# MIMXRT1042 register map
Vendor: nxp.com; File version: 1.0
CPU: CM7 r0p1, little endian, MPU, FPU, VTOR, 4 interrupt priority bits
Registers are 32-bit, read-write, reset 0x0 unless marked. A register's access mark holds for its fields unless they carry their own. Offsets are from the block's base; [hi:lo] are bit positions; 'fields as' and 'values as' point back to an identical list.

## XTALOSC24M
Base 0x400D8000; register names take the prefix XTALOSC24M_; alternate view of CCM_ANALOG
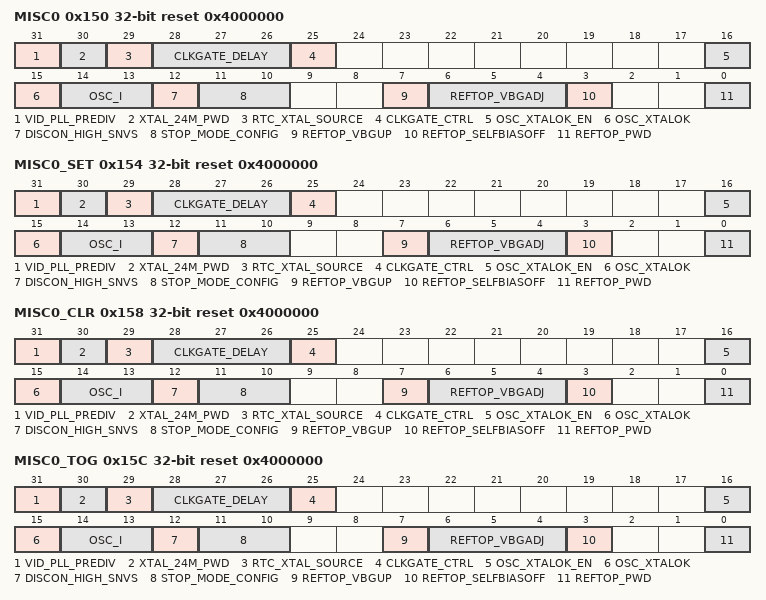
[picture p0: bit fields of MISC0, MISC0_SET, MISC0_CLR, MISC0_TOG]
0x150 MISC0 reset 0x4000000 — Miscellaneous Register 0
  [31] VID_PLL_PREDIV — Predivider for the source clock of the PLL's. Not related to oscillator.
    0=Divide by 1; 1=Divide by 2
  [30] XTAL_24M_PWD — This field powers down the 24M crystal oscillator if set true.
  [29] RTC_XTAL_SOURCE ro — This field indicates which chip source is being used for the rtc clock.
    0=Internal ring oscillator; 1=RTC_XTAL
  [28:26] CLKGATE_DELAY — This field specifies the delay between powering up the XTAL 24MHz clock and releasing the clock to the digital logic inside the analog block
    0=0.5ms; 1=1.0ms; 2=2.0ms; 3=3.0ms; 4=4.0ms; 5=5.0ms; 6=6.0ms; 7=7.0ms
  [25] CLKGATE_CTRL — This bit allows disabling the clock gate (always ungated) for the xtal 24MHz clock that clocks the digital logic in the analog block
    0=ALLOW_AUTO_GATE (Allow the logic to automatically gate the clock when the XTAL is powered down.); 1=NO_AUTO_GATE (Prevent the logic from ever gating off the clock.)
  [16] OSC_XTALOK_EN — This bit enables the detector that signals when the 24MHz crystal oscillator is stable.
  [15] OSC_XTALOK ro — Status bit that signals that the output of the 24-MHz crystal oscillator is stable
  [14:13] OSC_I — This field determines the bias current in the 24MHz oscillator
    0=NOMINAL; 1=MINUS_12_5_PERCENT (Decrease current by 12.5%); 2=MINUS_25_PERCENT (Decrease current by 25.0%); 3=MINUS_37_5_PERCENT (Decrease current by 37.5%)
  [12] DISCON_HIGH_SNVS — This bit controls a switch from VDD_HIGH_IN to VDD_SNVS_IN.
    0=Turn on the switch; 1=Turn off the switch
  [11:10] STOP_MODE_CONFIG — Configure the analog behavior in stop mode. Not related to oscillator.
    0=All analog except rtc powered down on stop mode assertion. XtalOsc=on, RCOsc=off;; 1=Certain analog functions such as certain regulators left up. XtalOsc=on, RCOsc=off;; 2=XtalOsc=off, RCOsc=on, Old BG=on, New BG=off; 3=XtalOsc=off, RCOsc=on, Old BG=off, New BG=on
  [7] REFTOP_VBGUP — Status bit that signals the analog bandgap voltage is up and stable
  [6:4] REFTOP_VBGADJ — Not related to oscillator.
    0=Nominal VBG; 1=VBG+0.78%; 2=VBG+1.56%; 3=VBG+2.34%; 4=VBG-0.78%; 5=VBG-1.56%; 6=VBG-2.34%; 7=VBG-3.12%
  [3] REFTOP_SELFBIASOFF — Control bit to disable the self-bias circuit in the analog bandgap
    0=Uses coarse bias currents for startup; 1=Uses bandgap-based bias currents for best performance
  [0] REFTOP_PWD — Control bit to power-down the analog bandgap reference circuitry
0x154 MISC0_SET reset 0x4000000 — Miscellaneous Register 0
  fields as MISC0
0x158 MISC0_CLR reset 0x4000000 — Miscellaneous Register 0
  fields as MISC0
0x15C MISC0_TOG reset 0x4000000 — Miscellaneous Register 0
  fields as MISC0
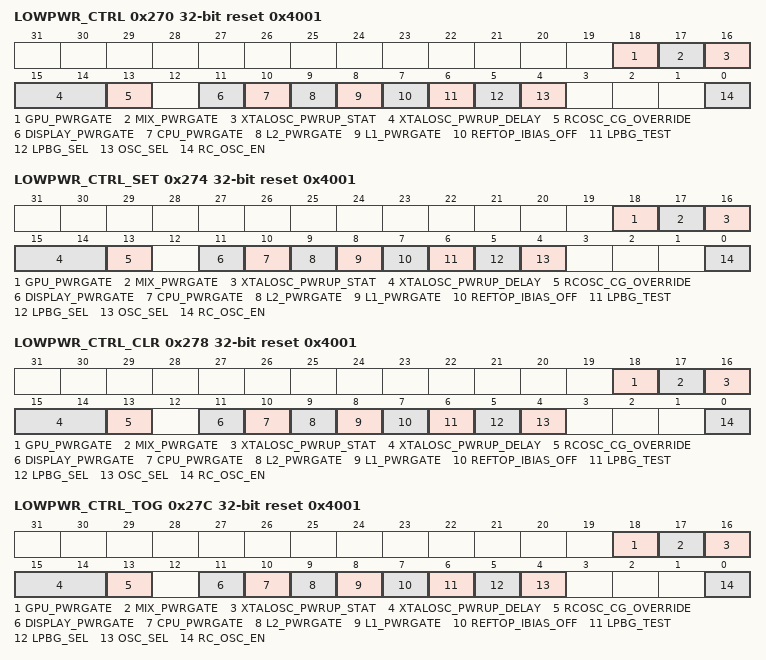
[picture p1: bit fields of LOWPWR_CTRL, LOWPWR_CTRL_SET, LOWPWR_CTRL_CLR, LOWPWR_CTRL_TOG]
0x270 LOWPWR_CTRL reset 0x4001 — XTAL OSC (LP) Control Register
  [18] GPU_PWRGATE — GPU power gate control. Used as software mask. Set to zero to force ungated.
  [17] MIX_PWRGATE — Display power gate control. Used as software mask. Set to zero to force ungated.
  [16] XTALOSC_PWRUP_STAT ro — Status of the 24MHz xtal oscillator.
    0=Not stable; 1=Stable and ready to use
  [15:14] XTALOSC_PWRUP_DELAY — Specifies the time delay between when the 24MHz xtal is powered up until it is stable and ready to use
    0=0.25ms; 1=0.5ms; 2=1ms; 3=2ms
  [13] RCOSC_CG_OVERRIDE — For debug purposes only
  [11] DISPLAY_PWRGATE — Display logic power gate control. Used as software override. Not related to oscillator.
  [10] CPU_PWRGATE — CPU power gate control. Used as software override. Test purpose only Not related to oscillator.
  [9] L2_PWRGATE — L2 power gate control. Used as software override. Not related to oscillator.
  [8] L1_PWRGATE — L1 power gate control. Used as software override. Not related to oscillator.
  [7] REFTOP_IBIAS_OFF — Low power reftop ibias disable. Not related to oscillator.
  [6] LPBG_TEST — Low power bandgap test bit. Not related to oscillator.
  [5] LPBG_SEL — Bandgap select. Not related to oscillator.
    0=Normal power bandgap; 1=Low power bandgap
  [4] OSC_SEL — Select the source for the 24MHz clock.
    0=XTAL OSC; 1=RC OSC
  [0] RC_OSC_EN — RC Osc. enable control.
    0=Use XTAL OSC to source the 24MHz clock; 1=Use RC OSC
0x274 LOWPWR_CTRL_SET reset 0x4001 — XTAL OSC (LP) Control Register
  fields as LOWPWR_CTRL
0x278 LOWPWR_CTRL_CLR reset 0x4001 — XTAL OSC (LP) Control Register
  fields as LOWPWR_CTRL
0x27C LOWPWR_CTRL_TOG reset 0x4001 — XTAL OSC (LP) Control Register
  fields as LOWPWR_CTRL
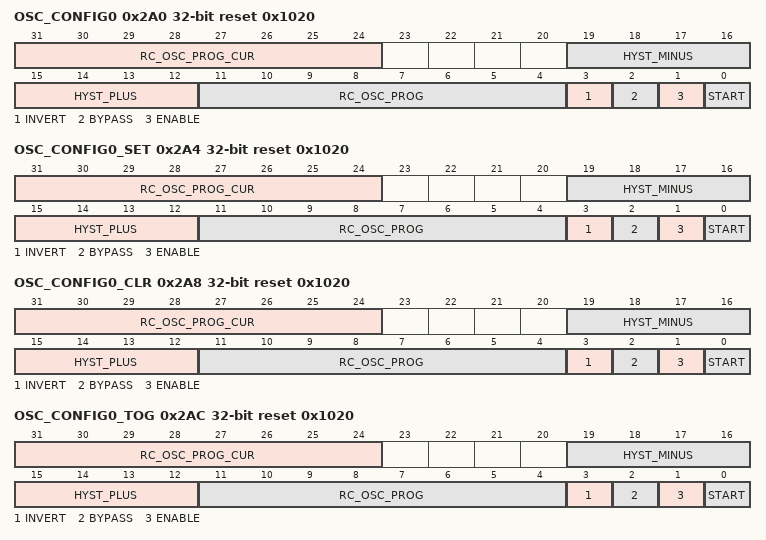
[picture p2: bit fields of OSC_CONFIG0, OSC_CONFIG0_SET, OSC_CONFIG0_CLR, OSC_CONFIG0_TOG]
0x2A0 OSC_CONFIG0 reset 0x1020 — XTAL OSC Configuration 0 Register
  [31:24] RC_OSC_PROG_CUR — The current tuning value in use.
  [19:16] HYST_MINUS — Negative hysteresis value
  [15:12] HYST_PLUS — Positive hysteresis value
  [11:4] RC_OSC_PROG — RC osc. tuning values.
  [3] INVERT — Invert the stepping of the calculated RC tuning value.
  [2] BYPASS — Bypasses any calculated RC tuning value and uses the programmed register value.
  [1] ENABLE — Enables the tuning logic to calculate new RC tuning values
  [0] START — Start/stop bit for the RC tuning calculation logic. If stopped the tuning logic is reset.
0x2A4 OSC_CONFIG0_SET reset 0x1020 — XTAL OSC Configuration 0 Register
  fields as OSC_CONFIG0
0x2A8 OSC_CONFIG0_CLR reset 0x1020 — XTAL OSC Configuration 0 Register
  fields as OSC_CONFIG0
0x2AC OSC_CONFIG0_TOG reset 0x1020 — XTAL OSC Configuration 0 Register
  fields as OSC_CONFIG0
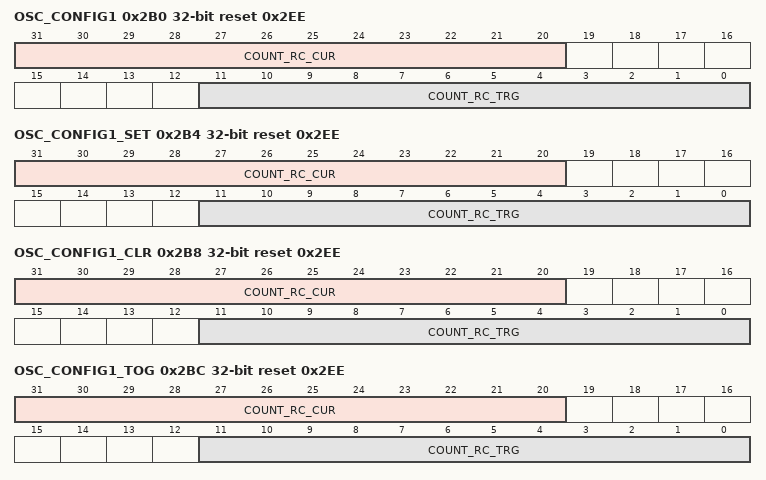
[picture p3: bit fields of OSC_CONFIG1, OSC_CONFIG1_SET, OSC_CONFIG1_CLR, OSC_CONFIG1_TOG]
0x2B0 OSC_CONFIG1 reset 0x2EE — XTAL OSC Configuration 1 Register
  [31:20] COUNT_RC_CUR — The current tuning value in use.
  [11:0] COUNT_RC_TRG — The target count used to tune the RC OSC frequency
0x2B4 OSC_CONFIG1_SET reset 0x2EE — XTAL OSC Configuration 1 Register
  fields as OSC_CONFIG1
0x2B8 OSC_CONFIG1_CLR reset 0x2EE — XTAL OSC Configuration 1 Register
  fields as OSC_CONFIG1
0x2BC OSC_CONFIG1_TOG reset 0x2EE — XTAL OSC Configuration 1 Register
  fields as OSC_CONFIG1
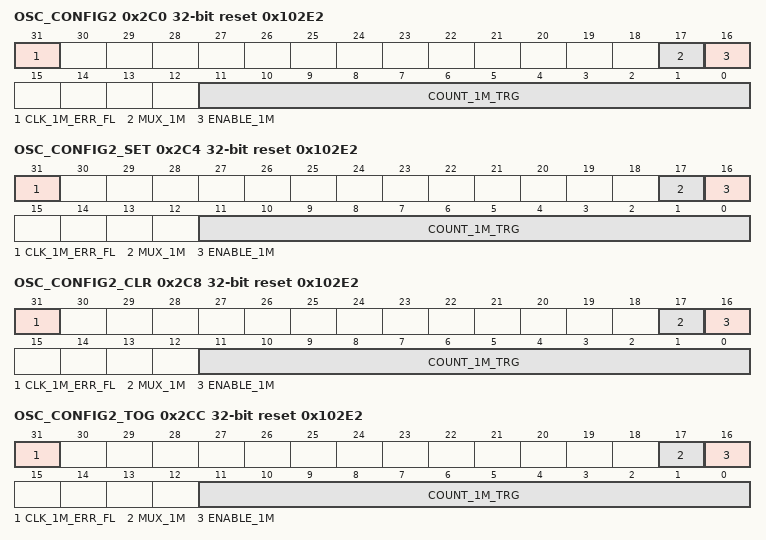
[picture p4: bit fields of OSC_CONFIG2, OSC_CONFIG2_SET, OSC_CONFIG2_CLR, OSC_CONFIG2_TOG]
0x2C0 OSC_CONFIG2 reset 0x102E2 — XTAL OSC Configuration 2 Register
  [31] CLK_1M_ERR_FL — Flag indicates that the count_1m count wasn't reached within 1 32kHz period
  [17] MUX_1M — Mux the corrected or uncorrected 1MHz clock to the output
  [16] ENABLE_1M — Enable the 1MHz clock output. 0 - disabled; 1 - enabled.
  [11:0] COUNT_1M_TRG — The target count used to tune the 1MHz clock frequency
0x2C4 OSC_CONFIG2_SET reset 0x102E2 — XTAL OSC Configuration 2 Register
  fields as OSC_CONFIG2
0x2C8 OSC_CONFIG2_CLR reset 0x102E2 — XTAL OSC Configuration 2 Register
  fields as OSC_CONFIG2
0x2CC OSC_CONFIG2_TOG reset 0x102E2 — XTAL OSC Configuration 2 Register
  fields as OSC_CONFIG2

## Notices in the file
Copyright 2016-2022 NXP
All rights reserved.
SPDX-License-Identifier: BSD-3-Clause
